# ISS_CTSET register map
Vendor: Texas Instruments
Peripheral module from a debugger description file (folder DM50x).
Registers are 32-bit, access per field, reset values left out (the file's numbers can be read two ways) unless marked. A register's access mark holds for its fields unless they carry their own. Offsets are as the file gives them; lines under a group give offsets from that group; [hi:lo] are bit positions; {n}, {i} and the like mark numbered series; 'fields as' and 'values as' point back to an identical list; <NAME> marks a mode.

## ISS_CTSET
0x00 CTSETIDEN ro — CTSET identification register.
  [31:0] REVISION — IP Revision
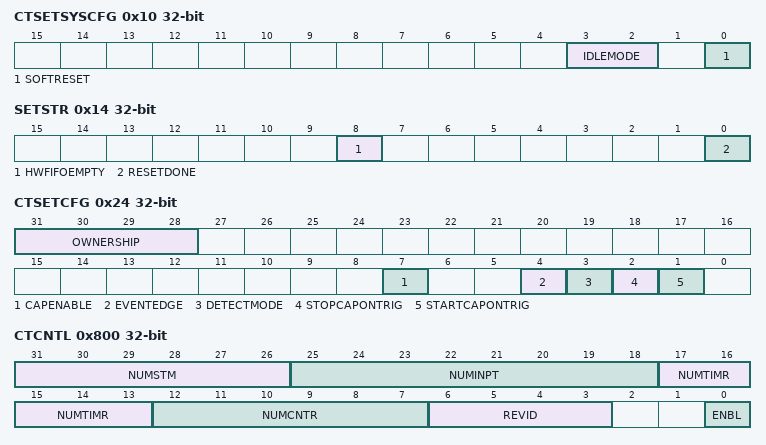
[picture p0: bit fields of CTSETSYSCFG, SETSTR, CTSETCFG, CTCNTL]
0x10 CTSETSYSCFG — CTSET system configuration register
  [3:2] IDLEMODE rw, [0] SOFTRESET rw
0x14 SETSTR ro — SET status register
  [8] HWFIFOEMPTY, [0] RESETDONE
0x24 CTSETCFG — CTSET configuration register
  [31:28] OWNERSHIP rw — Claim control and status.
  [7] CAPENABLE rw — When high, the system event capture is enabled.
  [4] EVENTEDGE rw — High or Low level event detection
  [3] DETECTMODE rw — Message generated based on event detection or sampling window.
  [2] STOPCAPONTRIG rw — Stop capturing system events from external trigger detection.
  [1] STARTCAPONTRIG rw — Start capturing systetm events from external trigger detection
0x28 SETSPLREG — System event sampling window register
  [7:0] WINDOWSIZE rw
0x30 SETEVTENBL1 rw — System event detection enable register 1
  [31:0] EVTENABLE — Event 1 to 32 detection enable bits. Bit 0 corresponds to Event 1, bit 1 is for event 2, ... , bit 31 is for event 32.
0x34 SETEVTENBL2 rw — System event detection enable register 2
  [31:0] EVTENABLE — Event 33 to 64 detection enable bits. Bit 0 corresponds to Event 33, bit 1 is for event 34, ... , bit 31 is for event 64.
{0x2C+4i} SETEVTENBL{i} rw (i=3..7)
  [31:0] EVTENABLE — Event {32i-31} to {32i} detection enable bits. Bit 0 corresponds to Event {32i-31}, bit 1 is for event {32i-30}, ... , bit 31 is for event {32i}.
0x4C SETEVTENBL8
  [30:0] EVTENABLE rw — Event 225 to 255 detection enable bits. Bit 0 corresponds to Event 225, bit 1 is for event 226, ... , bit 31 is for event 255.
0x50 SETMSTID — System Event Master ID. Note that the reset value is not necessarily 0 but based on tieoff value at CTSET boundary.
  [7:0] MASTID rw — HW Master ID for SET.
0x800 CTCNTL — Counter Timer Control
  [31:26] NUMSTM ro, [25:18] NUMINPT ro, [17:13] NUMTIMR ro, [12:7] NUMCNTR ro, [6:3] REVID ro, [0] ENBL rw
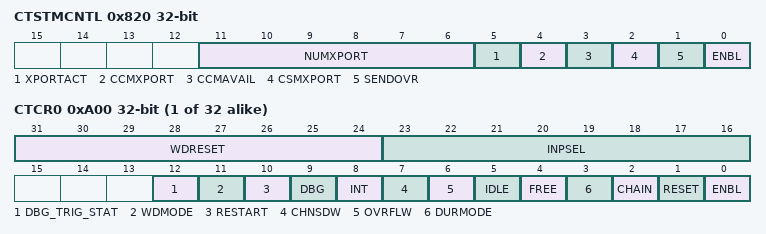
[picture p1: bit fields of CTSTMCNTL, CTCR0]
0x820 CTSTMCNTL — Counter Timer STM Control
  [11:6] NUMXPORT rw, [5] XPORTACT ro, [4] CCMXPORT rw, [3] CCMAVAIL ro, [2] CSMXPORT rw, [1] SENDOVR rw, [0] ENBL rw
0x824 CTSTMMSTID — CTM STM Master ID register.
  [7:0] MASTID rw
0x828 CTSTMINTVL — CTM STM interval register.
  [15:0] INTERVAL rw
0x82C CTSTMSEL0 rw — CTM STM counter select register.
  [31:0] COUNTSEL
0x830 CTSTMSEL1 rw — CTM STM counter select register.
  [31:0] COUNTSEL
{0x840+4i} TINTVLR{i} rw (i=0..15) — Timer Interval Register {i}
  [31:0] INTERVAL
0x8C0 CTNUMDBG ro — CTM Debug Event Register
  [3:0] NUMEVNT
{0x8C4+4i} CTDBGSGL{i} (i=0..7) — CTM Debug Event Register
  [7:0] INPSEL rw
0x9F0 CTGNBL0 rw — CTM Global Enable Register 0
  [31:0] ENABLE
0x9F4 CTGNBL1 rw — CTM Global Enable Register 1
  [31:0] ENABLE
0x9F8 CTGRST0 rw — CTM Global Reset Register 0
  [31:0] RESET
0x9FC CTGRST1 rw — CTM Global Reset Register 0
  [31:0] RESET
{0xA00+4i} CTCR{i} (i=0..31) — Counter Timer Control Register
  [31:24] WDRESET rw, [23:16] INPSEL rw, [12] DBG_TRIG_STAT rw, [11] WDMODE rw, [10] RESTART rw, [9] DBG rw, [8] INT rw, [7] CHNSDW ro, [6] OVRFLW ro, [5] IDLE rw, [4] FREE rw, [3] DURMODE rw, [2] CHAIN rw, [1] RESET wo, [0] ENBL rw
{0xB00+4i} CTCNTR{i} ro (i=0..31) — Counter Timer Counter Register
  [31:0] COUNT
0xC00 CTEOI — Counter Timer EOI Register
  [0] EOI rw
0xC04 CTIRQSTAT_RAW — Counter Timer IRQ raw status register
  [7:0] TIM_INT_IRQ rw
0xC08 CTIRQSTAT — Counter Timer IRQ Status Register
  [7:0] TIM_INT rw
0xC0C CTIRQENABLE_SET — Counter Timer IRQ eable set register
  [7:0] TIM_INT_IES rw
0xC10 CTIRQENABLE_CLR — Counter Timer IRQ enable clear register.
  [7:0] TIM_INT_IEC rw
